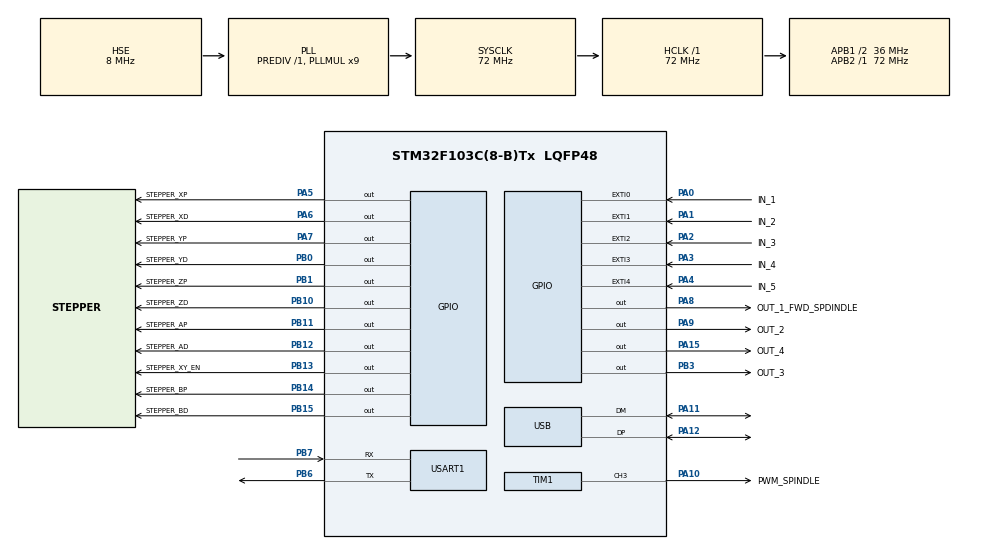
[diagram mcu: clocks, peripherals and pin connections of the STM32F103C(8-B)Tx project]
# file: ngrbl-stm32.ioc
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Mcu.Family=STM32F1
Mcu.Name=STM32F103C(8-B)Tx
Mcu.Package=LQFP48
NVIC.EXTI0_IRQn=true\:0\:0\:false\:false\:true\:true\:true
NVIC.EXTI1_IRQn=true\:0\:0\:false\:false\:true\:true\:true
NVIC.EXTI2_IRQn=true\:0\:0\:false\:false\:true\:true\:true
NVIC.EXTI3_IRQn=true\:0\:0\:false\:false\:true\:true\:true
NVIC.EXTI4_IRQn=true\:0\:0\:false\:false\:true\:true\:true
NVIC.PriorityGroup=NVIC_PRIORITYGROUP_4
NVIC.TIM2_IRQn=true\:0\:0\:false\:false\:true\:true\:true
NVIC.TIM3_IRQn=true\:0\:0\:false\:false\:true\:true\:true
NVIC.USB_LP_CAN1_RX0_IRQn=true\:0\:0\:false\:false\:true\:false\:true
PA0-WKUP.GPIO_Label=IN_1
PA0-WKUP.Signal=GPXTI0
PA1.GPIO_Label=IN_2
PA1.Signal=GPXTI1
PA10.GPIO_Label=PWM_SPINDLE
PA10.Signal=S_TIM1_CH3
PA11.Mode=Device
PA11.Signal=USB_DM
PA12.Mode=Device
PA12.Signal=USB_DP
PA13.Mode=Serial_Wire
PA13.Signal=SYS_JTMS-SWDIO
PA14.Mode=Serial_Wire
PA14.Signal=SYS_JTCK-SWCLK
PA15.GPIO_Label=OUT_4
PA15.Signal=GPIO_Output
PA2.GPIO_Label=IN_3
PA2.Signal=GPXTI2
PA3.GPIO_Label=IN_4
PA3.Signal=GPXTI3
PA4.GPIO_Label=IN_5
PA4.Signal=GPXTI4
PA5.GPIO_Label=STEPPER_XP
PA5.Signal=GPIO_Output
PA6.GPIO_Label=STEPPER_XD
PA6.Signal=GPIO_Output
PA7.GPIO_Label=STEPPER_YP
PA7.Signal=GPIO_Output
PA8.GPIO_Label=OUT_1_FWD_SPDINDLE
PA8.Signal=GPIO_Output
PA9.GPIO_Label=OUT_2
PA9.Signal=GPIO_Output
PB0.GPIO_Label=STEPPER_YD
PB0.Signal=GPIO_Output
PB1.GPIO_Label=STEPPER_ZP
PB1.Signal=GPIO_Output
PB10.GPIO_Label=STEPPER_ZD
PB10.Signal=GPIO_Output
PB11.GPIO_Label=STEPPER_AP
PB11.Signal=GPIO_Output
PB12.GPIO_Label=STEPPER_AD
PB12.Signal=GPIO_Output
PB13.GPIO_Label=STEPPER_XY_EN
PB13.Signal=GPIO_Output
PB14.GPIO_Label=STEPPER_BP
PB14.Signal=GPIO_Output
PB15.GPIO_Label=STEPPER_BD
PB15.Signal=GPIO_Output
PB3.GPIO_Label=OUT_3
PB3.Signal=GPIO_Output
PB6.Mode=Asynchronous
PB6.Signal=USART1_TX
PB7.Mode=Asynchronous
PB7.Signal=USART1_RX
PD0-OSC_IN.Mode=HSE-External-Oscillator
PD0-OSC_IN.Signal=RCC_OSC_IN
PD1-OSC_OUT.Mode=HSE-External-Oscillator
PD1-OSC_OUT.Signal=RCC_OSC_OUT
ProjectManager.HeapSize=0x200
ProjectManager.StackSize=0x400
ProjectManager.TargetToolchain=Makefile
RCC.AHBFreq_Value=72000000
RCC.APB1CLKDivider=RCC_HCLK_DIV2
RCC.APB1Freq_Value=36000000
RCC.APB1TimFreq_Value=72000000
RCC.APB2Freq_Value=72000000
RCC.APB2TimFreq_Value=72000000
RCC.HCLKFreq_Value=72000000
RCC.PLLMUL=RCC_PLL_MUL9
RCC.SYSCLKFreq_VALUE=72000000
RCC.SYSCLKSource=RCC_SYSCLKSOURCE_PLLCLK
RCC.USBFreq_Value=48000000
RCC.USBPrescaler=RCC_USBCLKSOURCE_PLL_DIV1_5
SH.S_TIM1_CH3.0=TIM1_CH3,PWM Generation3 CH3
TIM1.Channel-PWM\ Generation3\ CH3=TIM_CHANNEL_3
TIM1.Period=32768
TIM2.Period=32768
TIM3.Channel-Output\ Compare1\ No\ Output=TIM_CHANNEL_1
TIM3.Period=32768
TIM3.Pulse-Output\ Compare1\ No\ Output=16000
TIM3.TIM_MasterOutputTrigger=TIM_TRGO_UPDATE
USART1.VirtualMode=VM_ASYNC
USB_DEVICE.CLASS_NAME_FS=CDC
USB_DEVICE.VirtualMode=Cdc
USB_DEVICE.VirtualModeFS=Cdc_FS
VP_TIM2_VS_ClockSourceINT.Mode=Internal
VP_TIM3_VS_ClockSourceINT.Mode=Internal
VP_TIM3_VS_no_output1.Mode=Output Compare1 No Output
VP_USB_DEVICE_VS_USB_DEVICE_CDC_FS.Mode=CDC_FS
board=custom

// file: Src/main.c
/* USER CODE BEGIN Header */
/**
  ******************************************************************************
  * @file           : main.c
  * @brief          : Main program body
  ******************************************************************************
  * @attention
  *
  * <h2><center>&copy; Copyright (c) 2019 STMicroelectronics.
  * All rights reserved.</center></h2>
  *
  * This software component is licensed by ST under Ultimate Liberty license
  * SLA0044, the "License"; You may not use this file except in compliance with
  * the License. You may obtain a copy of the License at:
  *                             www.st.com/SLA0044
  *
  ******************************************************************************
  */
/* USER CODE END Header */

#include "main.h"
#include "tim.h"
#include "usart.h"
#include "usb_device.h"
#include "gpio.h"

/* USER CODE BEGIN Includes */

#include "f_eeprom.h"

/* USER CODE END Includes */

void SystemClock_Config(void);

int main(void)
{

  /* MCU Configuration--------------------------------------------------------*/

  /* Reset of all peripherals, Initializes the Flash interface and the Systick. */
  HAL_Init();

  /* Configure the system clock */
  SystemClock_Config();

  /* Initialize all configured peripherals */
  MX_GPIO_Init();
  MX_TIM1_Init();
  MX_USART1_UART_Init();
  MX_USB_DEVICE_Init();
  MX_TIM2_Init();
  MX_TIM3_Init();
  /* USER CODE BEGIN 2 */

  __disable_irq();
  HAL_FLASH_Unlock();

  EE_Init();

  HAL_FLASH_Lock();
  __enable_irq();

  ngrbl_init();

  ngrbl_main_loop();

  /* USER CODE END 2 */

  /* Infinite loop */
  while (1)
  {

  }
}

void SystemClock_Config(void)
{
  RCC_OscInitTypeDef RCC_OscInitStruct = {0};
  RCC_ClkInitTypeDef RCC_ClkInitStruct = {0};
  RCC_PeriphCLKInitTypeDef PeriphClkInit = {0};

  /** Initializes the CPU, AHB and APB busses clocks
  */
  RCC_OscInitStruct.OscillatorType = RCC_OSCILLATORTYPE_HSE;
  RCC_OscInitStruct.HSEState = RCC_HSE_ON;
  RCC_OscInitStruct.HSEPredivValue = RCC_HSE_PREDIV_DIV1;
  RCC_OscInitStruct.HSIState = RCC_HSI_ON;
  RCC_OscInitStruct.PLL.PLLState = RCC_PLL_ON;
  RCC_OscInitStruct.PLL.PLLSource = RCC_PLLSOURCE_HSE;
  RCC_OscInitStruct.PLL.PLLMUL = RCC_PLL_MUL9;
  if (HAL_RCC_OscConfig(&RCC_OscInitStruct) != HAL_OK)
  {
    Error_Handler();
  }
  /** Initializes the CPU, AHB and APB busses clocks
  */
  RCC_ClkInitStruct.ClockType = RCC_CLOCKTYPE_HCLK|RCC_CLOCKTYPE_SYSCLK
                              |RCC_CLOCKTYPE_PCLK1|RCC_CLOCKTYPE_PCLK2;
  RCC_ClkInitStruct.SYSCLKSource = RCC_SYSCLKSOURCE_PLLCLK;
  RCC_ClkInitStruct.AHBCLKDivider = RCC_SYSCLK_DIV1;
  RCC_ClkInitStruct.APB1CLKDivider = RCC_HCLK_DIV2;
  RCC_ClkInitStruct.APB2CLKDivider = RCC_HCLK_DIV1;

  if (HAL_RCC_ClockConfig(&RCC_ClkInitStruct, FLASH_LATENCY_2) != HAL_OK)
  {
    Error_Handler();
  }
  PeriphClkInit.PeriphClockSelection = RCC_PERIPHCLK_USB;
  PeriphClkInit.UsbClockSelection = RCC_USBCLKSOURCE_PLL_DIV1_5;
  if (HAL_RCCEx_PeriphCLKConfig(&PeriphClkInit) != HAL_OK)
  {
    Error_Handler();
  }
}

void Error_Handler(void)
{
}

/************************ (C) COPYRIGHT STMicroelectronics *****END OF FILE****/
